# MKL28T7_CORE1 register map
Vendor: Freescale Semiconductor, Inc.; Series: Kinetis_L; File version: 1.6
CPU: CM0PLUS r0p0, little endian, no MPU, no FPU, VTOR, 2 interrupt priority bits
Registers are 32-bit, read-write, reset 0x0 unless marked. A register's access mark holds for its fields unless they carry their own. Offsets are from the block's base; [hi:lo] are bit positions; 'fields as' and 'values as' point back to an identical list.

## ASMC — ASMC (Auxiliary System Mode Control) Module
Base 0x400F5000; register names take the prefix ASMC_
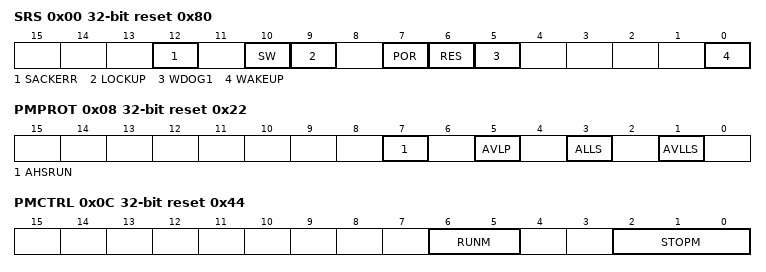
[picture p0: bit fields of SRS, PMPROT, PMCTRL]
0x00 SRS ro reset 0x80 — System Reset Status Register
  [12] SACKERR — Stop Mode Acknowledge Error Reset
    0=Reset not caused by peripheral failure to acknowledge attempt to enter stop mode; 1=Reset caused by peripheral failure to acknowledge attempt to enter stop mode
  [10] SW — Software
    0=Reset not caused by software setting of SYSRESETREQ bit; 1=Reset caused by software setting of SYSRESETREQ bit
  [9] LOCKUP — Core 1 Lockup
    0=Reset not caused by core LOCKUP event; 1=Reset caused by core LOCKUP event
  [7] POR — Power-On Reset
    0=Reset not caused by POR; 1=Reset caused by POR
  [6] RES — Chip Reset not POR
    0=Chip Reset did not occur; 1=Chip Reset caused by a source other than POR occured
  [5] WDOG1 — Watchdog
    0=Reset not caused by watchdog timeout; 1=Reset caused by watchdog timeout
  [0] WAKEUP — Low Leakage Wakeup Reset
    0=Reset not caused by LLWU module wakeup source; 1=Reset caused by LLWU module wakeup source
0x08 PMPROT reset 0x22 — Power Mode Protection register
  [7] AHSRUN — Allow High Speed Run mode
    0=HSRUN is not allowed; 1=HSRUN is allowed
  [5] AVLP — Allow Very-Low-Power Modes
    0=VLPR, VLPW, and VLPS are not allowed; 1=VLPR, VLPW, and VLPS are allowed
  [3] ALLS — Allow Low-Leakage Stop Mode
    0=Any LLSx mode is not allowed; 1=Any LLSx mode is allowed
  [1] AVLLS — Allow Very-Low-Leakage Stop Mode
    0=Any VLLSx mode is not allowed; 1=Any VLLSx mode is allowed
0x0C PMCTRL reset 0x44 — Power Mode Control register
  [6:5] RUNM — Run Mode Control
    0=Normal Run mode (RUN); 2=Very-Low-Power Run mode (VLPR); 3=High Speed Run mode (HSRUN)
  [2:0] STOPM — Stop Mode Control
    0=Normal Stop (STOP); 2=Very-Low-Power Stop (VLPS); 3=Low-Leakage Stop (LLSx); 4=Very-Low-Leakage Stop (VLLSx); 6=Reseved
0x10 STOPCTRL — Stop Control Register
  [7:6] PSTOPO — Partial Stop Option
    0=STOP - Normal Stop mode; 1=PSTOP1 - Partial Stop with both system and bus clocks disabled; 2=PSTOP2 - Partial Stop with system clock disabled and bus clock enabled
0x14 PMSTAT ro reset 0x4 — Power Mode Status register
  [7:0] PMSTAT — Power Mode Status

## PCC1
Base 0x400FA000
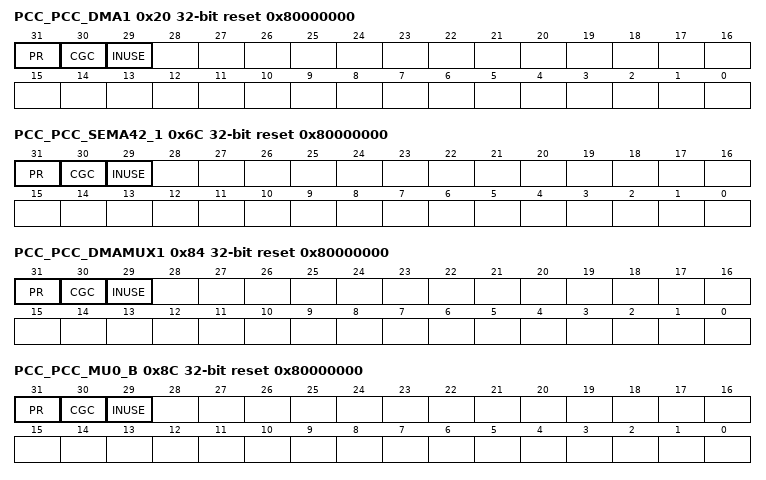
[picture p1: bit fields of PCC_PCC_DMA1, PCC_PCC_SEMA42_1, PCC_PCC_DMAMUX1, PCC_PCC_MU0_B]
0x20 PCC_PCC_DMA1 reset 0x80000000 — PCC_DMA1 Register
  [31] PR ro — Enable
    0=Peripheral is not present; 1=Peripheral is present
  [30] CGC — Clock Gate Control
    0=Clock disabled; 1=Clock enabled
  [29] INUSE ro — Clock Gate Control
    0=Another core is not using this peripheral; 1=Another core is using this peripheral. Software cannot modify the existing clocking configuration.
0x6C PCC_PCC_SEMA42_1 reset 0x80000000 — PCC_SEMA42_1 Register
  fields as PCC_PCC_DMA1
0x84 PCC_PCC_DMAMUX1 reset 0x80000000 — PCC_DMAMUX1 Register
  fields as PCC_PCC_DMA1
0x8C PCC_PCC_MU0_B reset 0x80000000 — PCC_MU0_B Register
  fields as PCC_PCC_DMA1
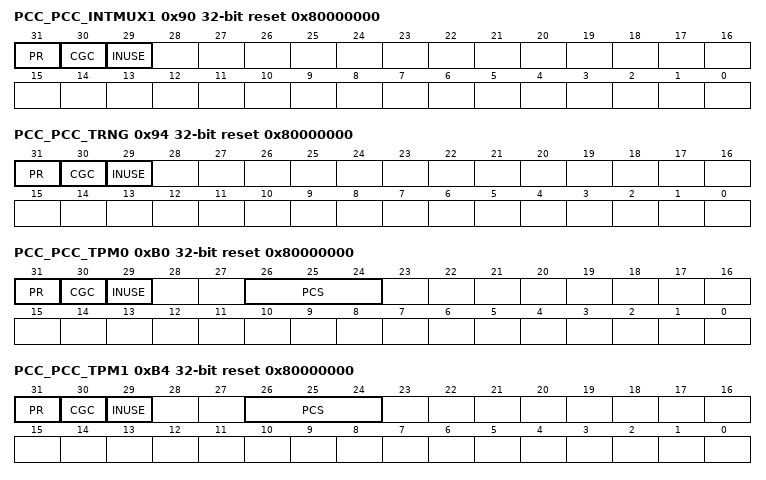
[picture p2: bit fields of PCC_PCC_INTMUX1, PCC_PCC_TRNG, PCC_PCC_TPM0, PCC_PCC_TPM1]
0x90 PCC_PCC_INTMUX1 reset 0x80000000 — PCC_INTMUX1 Register
  fields as PCC_PCC_DMA1
0x94 PCC_PCC_TRNG reset 0x80000000 — PCC_TRNG Register
  fields as PCC_PCC_DMA1
0xB0 PCC_PCC_TPM0 reset 0x80000000 — PCC_TPM0 Register
  [31] PR ro — Enable
    0=Peripheral is not present; 1=Peripheral is present
  [30] CGC — Clock Gate Control
    0=Clock disabled; 1=Clock enabled
  [29] INUSE ro — Clock Gate Control
    values as PCC_PCC_DMA1.INUSE
  [26:24] PCS — Peripheral Clock Source Select
    0=Clock is off (or test clock is enabled); 1=OSCCLK - System Oscillator Bus Clock(scg_sosc_slow_clk); 2=SCGIRCLK - Slow IRC Clock(scg_sirc_slow_clk), (maximum is 8MHz); 3=SCGFIRCLK - Fast IRC Clock(scg_firc_slow_clk), (maximum is 48MHz); 6=SCGPCLK System PLL clock (scg_spll_slow_clk)
0xB4 PCC_PCC_TPM1 reset 0x80000000 — PCC_TPM1 Register
  fields as PCC_PCC_TPM0
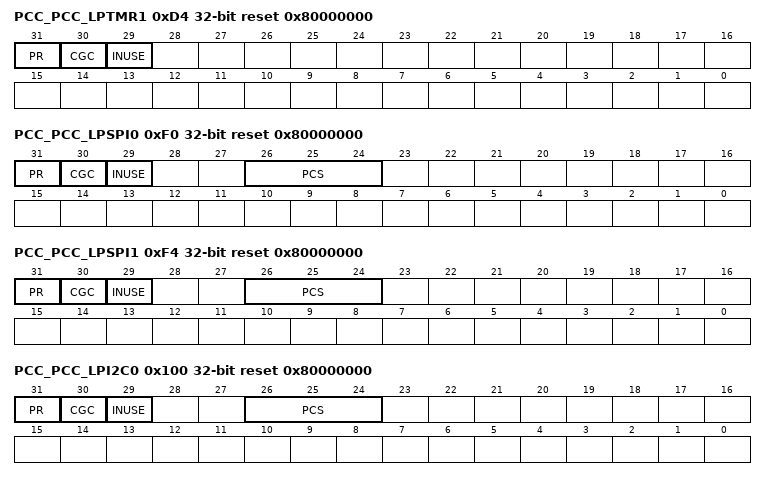
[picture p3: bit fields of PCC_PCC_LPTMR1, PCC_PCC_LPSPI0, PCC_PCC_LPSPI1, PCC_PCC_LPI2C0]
0xD4 PCC_PCC_LPTMR1 reset 0x80000000 — PCC_LPTMR1 Register
  fields as PCC_PCC_DMA1
0xF0 PCC_PCC_LPSPI0 reset 0x80000000 — PCC_LPSPI0 Register
  fields as PCC_PCC_TPM0
0xF4 PCC_PCC_LPSPI1 reset 0x80000000 — PCC_LPSPI1 Register
  fields as PCC_PCC_TPM0
0x100 PCC_PCC_LPI2C0 reset 0x80000000 — PCC_LPI2C0 Register
  fields as PCC_PCC_TPM0
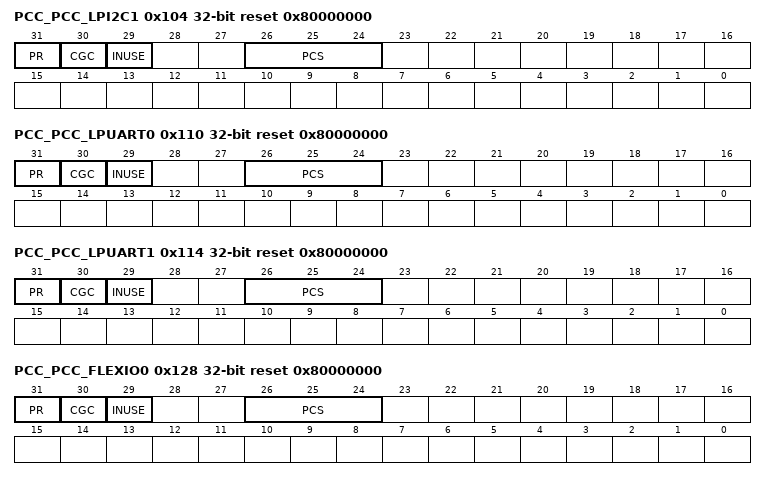
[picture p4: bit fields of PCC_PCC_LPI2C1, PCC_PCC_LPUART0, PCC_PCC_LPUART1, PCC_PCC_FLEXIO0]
0x104 PCC_PCC_LPI2C1 reset 0x80000000 — PCC_LPI2C1 Register
  fields as PCC_PCC_TPM0
0x110 PCC_PCC_LPUART0 reset 0x80000000 — PCC_LPUART0 Register
  fields as PCC_PCC_TPM0
0x114 PCC_PCC_LPUART1 reset 0x80000000 — PCC_LPUART1 Register
  fields as PCC_PCC_TPM0
0x128 PCC_PCC_FLEXIO0 reset 0x80000000 — PCC_FLEXIO0 Register
  fields as PCC_PCC_TPM0
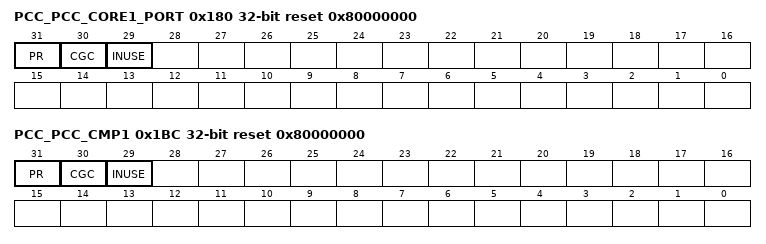
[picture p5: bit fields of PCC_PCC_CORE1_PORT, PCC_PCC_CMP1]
0x180 PCC_PCC_CORE1_PORT reset 0x80000000 — PCC_CORE1_PORT Register
  fields as PCC_PCC_DMA1
0x1BC PCC_PCC_CMP1 reset 0x80000000 — PCC_CMP1 Register
  fields as PCC_PCC_DMA1
